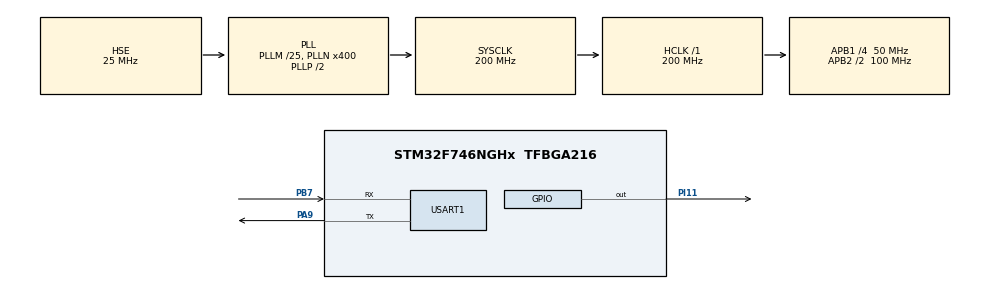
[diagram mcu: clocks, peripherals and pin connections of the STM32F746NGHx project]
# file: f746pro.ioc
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FREERTOS.Tasks01=defaultTask,24,128,StartDefaultTask,Default,NULL,Dynamic,NULL,NULL
Mcu.Family=STM32F7
Mcu.Name=STM32F746NGHx
Mcu.Package=TFBGA216
NVIC.PriorityGroup=NVIC_PRIORITYGROUP_4
NVIC.TIM1_UP_TIM10_IRQn=true\:0\:0\:false\:false\:true\:false\:false\:true
NVIC.TimeBase=TIM1_UP_TIM10_IRQn
NVIC.TimeBaseIP=TIM1
PA13.Mode=Serial_Wire
PA13.Signal=SYS_JTMS-SWDIO
PA14.Mode=Serial_Wire
PA14.Signal=SYS_JTCK-SWCLK
PA9.Mode=Asynchronous
PA9.Signal=USART1_TX
PB7.Mode=Asynchronous
PB7.Signal=USART1_RX
PH0/OSC_IN.Mode=HSE-External-Oscillator
PH0/OSC_IN.Signal=RCC_OSC_IN
PH1/OSC_OUT.Mode=HSE-External-Oscillator
PH1/OSC_OUT.Signal=RCC_OSC_OUT
PI11.Signal=GPIO_Output
ProjectManager.HeapSize=0x200
ProjectManager.StackSize=0x400
ProjectManager.TargetToolchain=Makefile
RCC.AHBFreq_Value=200000000
RCC.APB1CLKDivider=RCC_HCLK_DIV4
RCC.APB1Freq_Value=50000000
RCC.APB1TimFreq_Value=100000000
RCC.APB2CLKDivider=RCC_HCLK_DIV2
RCC.APB2Freq_Value=100000000
RCC.APB2TimFreq_Value=200000000
RCC.CortexFreq_Value=200000000
RCC.HCLKFreq_Value=200000000
RCC.HSE_VALUE=25000000
RCC.HSI_VALUE=16000000
RCC.PLL48CLockSelection=RCC_CLK48SOURCE_PLLSAIP
RCC.PLLI2SN=100
RCC.PLLM=25
RCC.PLLN=400
RCC.PLLQ=9
RCC.PLLSAIN=384
RCC.PLLSAIP=RCC_PLLSAIP_DIV8
RCC.PLLSAIR=5
RCC.PLLSAIRDiv=RCC_PLLSAIDIVR_8
RCC.PLLSourceVirtual=RCC_PLLSOURCE_HSE
RCC.SDMMCClockSelection=RCC_SDMMC1CLKSOURCE_CLK48
RCC.SYSCLKFreq_VALUE=200000000
RCC.SYSCLKSource=RCC_SYSCLKSOURCE_PLLCLK
RCC.USBFreq_Value=48000000
RCC.VCOOutputFreq_Value=400000000
USART1.VirtualMode-Asynchronous=VM_ASYNC
VP_FREERTOS_VS_CMSIS_V2.Mode=CMSIS_V2
VP_SYS_VS_tim1.Mode=TIM1
board=STM32F746G-DISCO

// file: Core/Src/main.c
/* USER CODE BEGIN Header */
/**
  ******************************************************************************
  * @file           : main.c
  * @brief          : Main program body
  ******************************************************************************
  * @attention
  *
  * <h2><center>&copy; Copyright (c) 2021 STMicroelectronics.
  * All rights reserved.</center></h2>
  *
  * This software component is licensed by ST under Ultimate Liberty license
  * SLA0044, the "License"; You may not use this file except in compliance with
  * the License. You may obtain a copy of the License at:
  *                             www.st.com/SLA0044
  *
  ******************************************************************************
  */
/* USER CODE END Header */
#include "main.h"
#include "cmsis_os.h"

/* USER CODE BEGIN Includes */
#include <SEGGER_SYSVIEW.h>
/* USER CODE END Includes */

UART_HandleTypeDef huart1;

/* Definitions for defaultTask */
osThreadId_t defaultTaskHandle;
const osThreadAttr_t defaultTask_attributes = {
  .name = "defaultTask",
  .stack_size = 128 * 4,
  .priority = (osPriority_t) osPriorityNormal,
};

void SystemClock_Config(void);
static void MX_GPIO_Init(void);
static void MX_USART1_UART_Init(void);
void StartDefaultTask(void *argument);

int main(void)
{

  /* MCU Configuration--------------------------------------------------------*/

  /* Reset of all peripherals, Initializes the Flash interface and the Systick. */
  HAL_Init();

  /* Configure the system clock */
  SystemClock_Config();

  /* Initialize all configured peripherals */
  MX_GPIO_Init();
  MX_USART1_UART_Init();
  /* USER CODE BEGIN 2 */
  //SEGGER_SYSTEM_view();
  /* USER CODE END 2 */

  /* Init scheduler */
  osKernelInitialize();
  SEGGER_SYSVIEW_Conf();

  /* Create the thread(s) */
  /* creation of defaultTask */
  defaultTaskHandle = osThreadNew(StartDefaultTask, NULL, &defaultTask_attributes);

  /* Start scheduler */
  osKernelStart();

  /* We should never get here as control is now taken by the scheduler */
  /* Infinite loop */
  while (1)
  {

  }
}

void SystemClock_Config(void)
{
  RCC_OscInitTypeDef RCC_OscInitStruct = {0};
  RCC_ClkInitTypeDef RCC_ClkInitStruct = {0};
  RCC_PeriphCLKInitTypeDef PeriphClkInitStruct = {0};

  /** Configure the main internal regulator output voltage
  */
  __HAL_RCC_PWR_CLK_ENABLE();
  __HAL_PWR_VOLTAGESCALING_CONFIG(PWR_REGULATOR_VOLTAGE_SCALE1);
  /** Initializes the RCC Oscillators according to the specified parameters
  * in the RCC_OscInitTypeDef structure.
  */
  RCC_OscInitStruct.OscillatorType = RCC_OSCILLATORTYPE_HSE;
  RCC_OscInitStruct.HSEState = RCC_HSE_ON;
  RCC_OscInitStruct.PLL.PLLState = RCC_PLL_ON;
  RCC_OscInitStruct.PLL.PLLSource = RCC_PLLSOURCE_HSE;
  RCC_OscInitStruct.PLL.PLLM = 25;
  RCC_OscInitStruct.PLL.PLLN = 400;
  RCC_OscInitStruct.PLL.PLLP = RCC_PLLP_DIV2;
  RCC_OscInitStruct.PLL.PLLQ = 9;
  if (HAL_RCC_OscConfig(&RCC_OscInitStruct) != HAL_OK)
  {
    Error_Handler();
  }
  /** Activate the Over-Drive mode
  */
  if (HAL_PWREx_EnableOverDrive() != HAL_OK)
  {
    Error_Handler();
  }
  /** Initializes the CPU, AHB and APB buses clocks
  */
  RCC_ClkInitStruct.ClockType = RCC_CLOCKTYPE_HCLK|RCC_CLOCKTYPE_SYSCLK
                              |RCC_CLOCKTYPE_PCLK1|RCC_CLOCKTYPE_PCLK2;
  RCC_ClkInitStruct.SYSCLKSource = RCC_SYSCLKSOURCE_PLLCLK;
  RCC_ClkInitStruct.AHBCLKDivider = RCC_SYSCLK_DIV1;
  RCC_ClkInitStruct.APB1CLKDivider = RCC_HCLK_DIV4;
  RCC_ClkInitStruct.APB2CLKDivider = RCC_HCLK_DIV2;

  if (HAL_RCC_ClockConfig(&RCC_ClkInitStruct, FLASH_LATENCY_6) != HAL_OK)
  {
    Error_Handler();
  }
  PeriphClkInitStruct.PeriphClockSelection = RCC_PERIPHCLK_USART1;
  PeriphClkInitStruct.Usart1ClockSelection = RCC_USART1CLKSOURCE_PCLK2;
  if (HAL_RCCEx_PeriphCLKConfig(&PeriphClkInitStruct) != HAL_OK)
  {
    Error_Handler();
  }
}

static void MX_USART1_UART_Init(void)
{

  huart1.Instance = USART1;
  huart1.Init.BaudRate = 115200;
  huart1.Init.WordLength = UART_WORDLENGTH_8B;
  huart1.Init.StopBits = UART_STOPBITS_1;
  huart1.Init.Parity = UART_PARITY_NONE;
  huart1.Init.Mode = UART_MODE_TX_RX;
  huart1.Init.HwFlowCtl = UART_HWCONTROL_NONE;
  huart1.Init.OverSampling = UART_OVERSAMPLING_16;
  huart1.Init.OneBitSampling = UART_ONE_BIT_SAMPLE_DISABLE;
  huart1.AdvancedInit.AdvFeatureInit = UART_ADVFEATURE_NO_INIT;
  if (HAL_UART_Init(&huart1) != HAL_OK)
  {
    Error_Handler();
  }

}

static void MX_GPIO_Init(void)
{
  GPIO_InitTypeDef GPIO_InitStruct = {0};

  /* GPIO Ports Clock Enable */
  __HAL_RCC_GPIOA_CLK_ENABLE();
  __HAL_RCC_GPIOB_CLK_ENABLE();
  __HAL_RCC_GPIOI_CLK_ENABLE();
  __HAL_RCC_GPIOH_CLK_ENABLE();

  /*Configure GPIO pin Output Level */
  HAL_GPIO_WritePin(GPIOI, GPIO_PIN_11, GPIO_PIN_RESET);

  /*Configure GPIO pin : PI11 */
  GPIO_InitStruct.Pin = GPIO_PIN_11;
  GPIO_InitStruct.Mode = GPIO_MODE_OUTPUT_PP;
  GPIO_InitStruct.Pull = GPIO_NOPULL;
  GPIO_InitStruct.Speed = GPIO_SPEED_FREQ_LOW;
  HAL_GPIO_Init(GPIOI, &GPIO_InitStruct);

}

void StartDefaultTask(void *argument)
{
  /* USER CODE BEGIN 5 */
  /* Infinite loop */
  for(;;)
  {
    HAL_GPIO_TogglePin(GPIOI, GPIO_PIN_1);
   // HAL_UART_Transmit(&huart6,"test\n",5,20);
    HAL_UART_Transmit(&huart1,"test123\r\n",8,20);
    osDelay(100);
  }
  /* USER CODE END 5 */
}

 /**
  * @brief  Period elapsed callback in non blocking mode
  * @note   This function is called  when TIM1 interrupt took place, inside
  * HAL_TIM_IRQHandler(). It makes a direct call to HAL_IncTick() to increment
  * a global variable "uwTick" used as application time base.
  * @param  htim : TIM handle
  * @retval None
  */
void HAL_TIM_PeriodElapsedCallback(TIM_HandleTypeDef *htim)
{
  if (htim->Instance == TIM1) {
    HAL_IncTick();
  }
}

void Error_Handler(void)
{
  __disable_irq();
  while (1)
  {
  }
}

/************************ (C) COPYRIGHT STMicroelectronics *****END OF FILE****/
